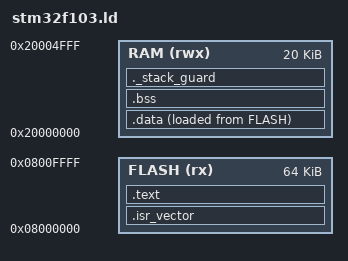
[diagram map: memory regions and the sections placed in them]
/* STM32F103C8 "Blue Pill": 64K flash, 20K RAM */
ENTRY(Reset_Handler)

MEMORY
{
  FLASH (rx)  : ORIGIN = 0x08000000, LENGTH = 64K
  RAM   (rwx) : ORIGIN = 0x20000000, LENGTH = 20K
}

_estack = ORIGIN(RAM) + LENGTH(RAM);

SECTIONS
{
  .isr_vector : { KEEP(*(.isr_vector)) } > FLASH

  .text :
  {
    *(.text*)
    *(.rodata*)
    . = ALIGN(4);
    _etext = .;
  } > FLASH

  /* unwind tables: nothing here throws, drop them */
  /DISCARD/ : { *(.ARM.exidx*) *(.ARM.extab*) }

  _sidata = LOADADDR(.data);
  .data :
  {
    . = ALIGN(4);
    _sdata = .;
    *(.data*)
    . = ALIGN(4);
    _edata = .;
  } > RAM AT > FLASH

  .bss :
  {
    . = ALIGN(4);
    _sbss = .;
    *(.bss*)
    *(COMMON)
    . = ALIGN(4);
    _ebss = .;
  } > RAM

  /* fail the link rather than silently overflow the stack into .bss */
  ._stack_guard :
  {
    . = ALIGN(8);
    . = . + 2K;
  } > RAM
}
